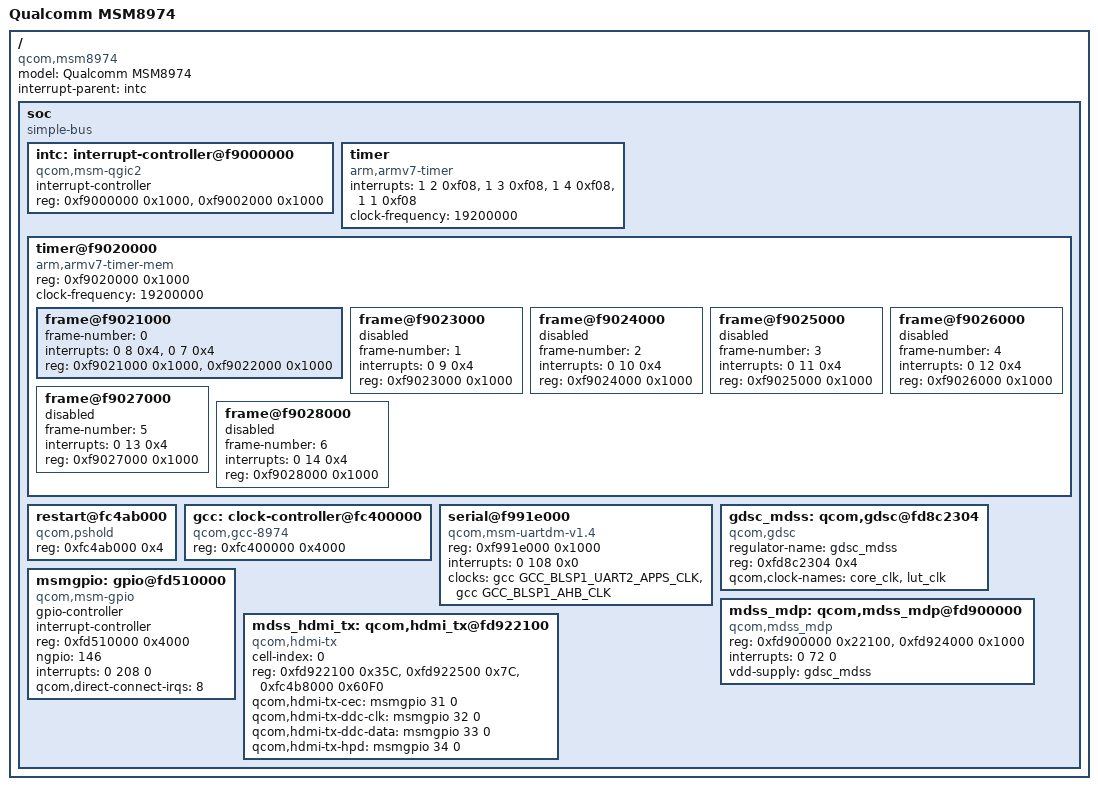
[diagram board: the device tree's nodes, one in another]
/dts-v1/;

#include "skeleton.dtsi"

#include <dt-bindings/clk/msm-gcc-8974.h>

/ {
	model = "Qualcomm MSM8974";
	compatible = "qcom,msm8974";
	interrupt-parent = <&intc>;

	soc: soc {
		#address-cells = <1>;
		#size-cells = <1>;
		ranges;
		compatible = "simple-bus";

		intc: interrupt-controller@f9000000 {
			compatible = "qcom,msm-qgic2";
			interrupt-controller;
			#interrupt-cells = <3>;
			reg = <0xf9000000 0x1000>,
			      <0xf9002000 0x1000>;
		};

		timer {
			compatible = "arm,armv7-timer";
			interrupts = <1 2 0xf08>,
				     <1 3 0xf08>,
				     <1 4 0xf08>,
				     <1 1 0xf08>;
			clock-frequency = <19200000>;
		};

		timer@f9020000 {
			#address-cells = <1>;
			#size-cells = <1>;
			ranges;
			compatible = "arm,armv7-timer-mem";
			reg = <0xf9020000 0x1000>;
			clock-frequency = <19200000>;

			frame@f9021000 {
				frame-number = <0>;
				interrupts = <0 8 0x4>,
					     <0 7 0x4>;
				reg = <0xf9021000 0x1000>,
				      <0xf9022000 0x1000>;
			};

			frame@f9023000 {
				frame-number = <1>;
				interrupts = <0 9 0x4>;
				reg = <0xf9023000 0x1000>;
				status = "disabled";
			};

			frame@f9024000 {
				frame-number = <2>;
				interrupts = <0 10 0x4>;
				reg = <0xf9024000 0x1000>;
				status = "disabled";
			};

			frame@f9025000 {
				frame-number = <3>;
				interrupts = <0 11 0x4>;
				reg = <0xf9025000 0x1000>;
				status = "disabled";
			};

			frame@f9026000 {
				frame-number = <4>;
				interrupts = <0 12 0x4>;
				reg = <0xf9026000 0x1000>;
				status = "disabled";
			};

			frame@f9027000 {
				frame-number = <5>;
				interrupts = <0 13 0x4>;
				reg = <0xf9027000 0x1000>;
				status = "disabled";
			};

			frame@f9028000 {
				frame-number = <6>;
				interrupts = <0 14 0x4>;
				reg = <0xf9028000 0x1000>;
				status = "disabled";
			};
		};

		restart@fc4ab000 {
			compatible = "qcom,pshold";
			reg = <0xfc4ab000 0x4>;
		};

		gcc: clock-controller@fc400000 {
			compatible = "qcom,gcc-8974", "qcom,gcc";
			#clock-cells = <1>;
			#reset-cells = <1>;
			reg = <0xfc400000 0x4000>;
		};

		serial@f991e000 {
			compatible = "qcom,msm-uartdm-v1.4", "qcom,msm-uartdm";
			reg = <0xf991e000 0x1000>;
			interrupts = <0 108 0x0>;
			clocks = <&gcc GCC_BLSP1_UART2_APPS_CLK>, <&gcc GCC_BLSP1_AHB_CLK>;
			clock-names = "core", "iface";
		};

		gdsc_mdss: qcom,gdsc@fd8c2304 {
			compatible = "qcom,gdsc";
			regulator-name = "gdsc_mdss";
			reg = <0xfd8c2304 0x4>;
			qcom,clock-names = "core_clk", "lut_clk";
			status = "ok";
		};

		msmgpio: gpio@fd510000 {
			compatible = "qcom,msm-gpio";
			gpio-controller;
			#gpio-cells = <2>;
			interrupt-controller;
			#interrupt-cells = <2>;
			reg = <0xfd510000 0x4000>;
			ngpio = <146>;
			interrupts = <0 208 0>;
			qcom,direct-connect-irqs = <8>;
		};

		mdss_mdp: qcom,mdss_mdp@fd900000 {
			compatible = "qcom,mdss_mdp";
			reg = <0xfd900000 0x22100>,
				<0xfd924000 0x1000>;
			reg-names = "mdp_phys", "vbif_phys";
			interrupts = <0 72 0>;
			vdd-supply = <&gdsc_mdss>;
		};

		mdss_hdmi_tx: qcom,hdmi_tx@fd922100 {
			cell-index = <0>;
			compatible = "qcom,hdmi-tx";
			reg =	<0xfd922100 0x35C>,
				<0xfd922500 0x7C>,
				<0xfc4b8000 0x60F0>;
			reg-names = "core_physical", "phy_physical", "qfprom_physical";

			qcom,hdmi-tx-cec = <&msmgpio 31 0>;
			qcom,hdmi-tx-ddc-clk = <&msmgpio 32 0>;
			qcom,hdmi-tx-ddc-data = <&msmgpio 33 0>;
			qcom,hdmi-tx-hpd = <&msmgpio 34 0>;
		};
	};
};
